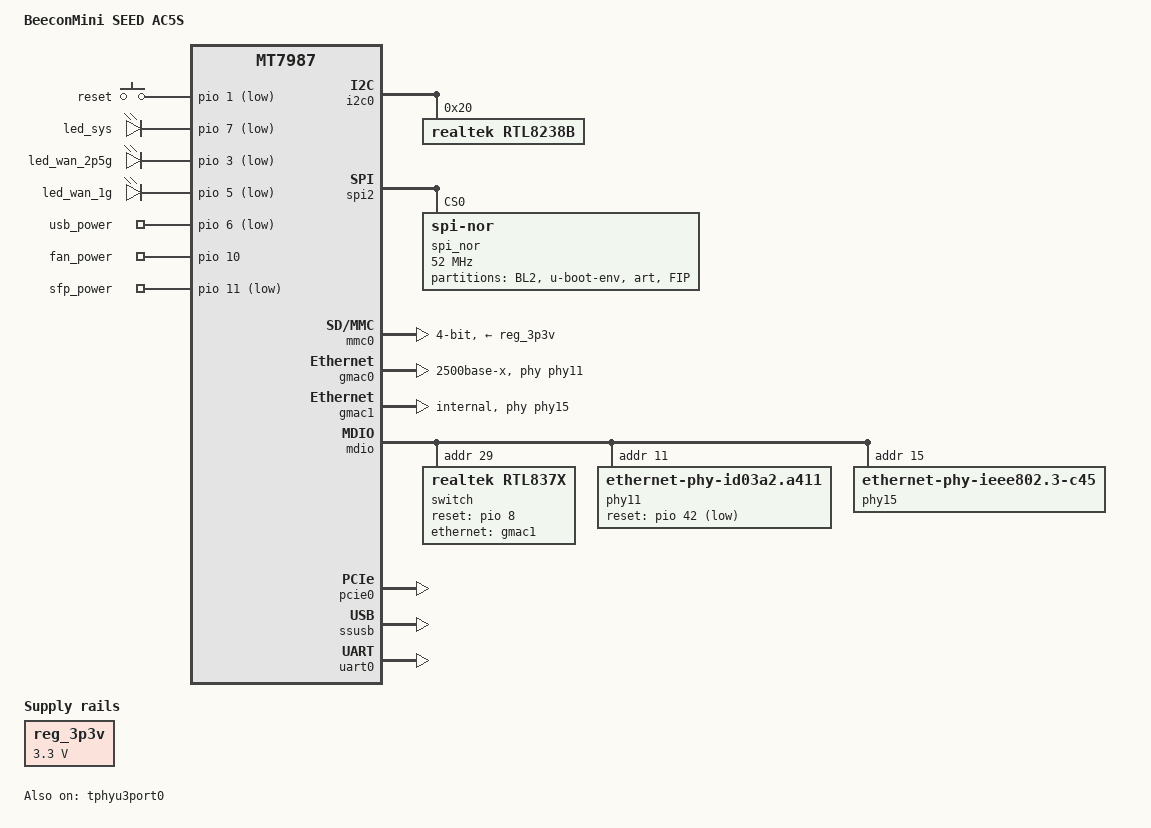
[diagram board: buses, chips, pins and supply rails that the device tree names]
// SPDX-License-Identifier: (GPL-2.0 OR MIT)
//
// BeeconMini SEED AC5S (eMMC/SD 变体) — kernel 6.18 / immortalwrt
// 基准: BeeconMini/immortalwrt 25.12.1 分支同名 DTS
// 改动: 交换芯片节点从 BeeconMini 闭源绑定 (realtek,rtl8373n + mediatek,mdio)
//       转换为社区开源驱动 rtl837x-gsw 的绑定 (realtek,rtl837x, mdio 子节点)

/dts-v1/;
#include "mt7987a.dtsi"
#include <dt-bindings/input/input.h>

/ {
	model = "BeeconMini SEED AC5S";
	compatible = "beeconmini,seed-ac5s", "mediatek,mt7987a", "mediatek,mt7987";

	aliases {
		label-mac-device = &gmac0;
		led-boot = &led_power;
		led-failsafe = &led_power;
		led-running = &led_power;
		led-upgrade = &led_power;
	};

	chosen {
		bootargs = "console=ttyS0,115200n1 \
			    earlycon=uart8250,mmio32,0x11000000 \
			    pci=pcie_bus_perf \
			    root=PARTLABEL=rootfs rootfstype=squashfs,f2fs \
			    rootwait fstools_partname_fallback_scan=1";
	};

	aliases {
		led-boot = &led_sys;
		led-failsafe = &led_sys;
		led-running = &led_sys;
		led-upgrade = &led_sys;
	};

	gpio-keys {
		compatible = "gpio-keys";

		reset {
			label = "reset";
			linux,code = <KEY_RESTART>;
			gpios = <&pio 1 GPIO_ACTIVE_LOW>;
			debounce-interval = <10>;
		};
	};

	gpio-leds {
		compatible = "gpio-leds";

		led_sys: led@0 {
			label = "led_sys";
			gpios = <&pio 7 GPIO_ACTIVE_LOW>;
		};

		led_wan_2p5g: led@1 {
			label = "led_wan_2p5g";
			gpios = <&pio 3 GPIO_ACTIVE_LOW>;
		};

		led_wan_1g: led@2 {
			label = "led_wan_1g";
			gpios = <&pio 5 GPIO_ACTIVE_LOW>;
		};
	};

	gpio-export {
		compatible = "gpio-export";
		#size-cells = <0>;

		usb {
			gpio-export,name = "usb_power";
			gpio-export,output = <0>;
			gpios = <&pio 6 GPIO_ACTIVE_LOW>;
		};

		fan {
			gpio-export,name = "fan_power";
			gpio-export,output = <0>;
			gpios = <&pio 10 GPIO_ACTIVE_HIGH>;
		};

		sfp {
			gpio-export,name = "sfp_power";
			gpio-export,output = <1>;
			gpios = <&pio 11 GPIO_ACTIVE_LOW>;
		};
	};

	reg_3p3v: regulator-3p3v {
		compatible = "regulator-fixed";
		regulator-name = "fixed-3.3V";
		regulator-min-microvolt = <3300000>;
		regulator-max-microvolt = <3300000>;
		regulator-boot-on;
		regulator-always-on;
	};
};

&i2c0 {
	status = "okay";
	rtl8238b: rtl8238b@20 {
		compatible = "realtek,rtl8238b";
		reg = <0x20>;
	};
};

&spi1 {
	status = "disabled";
};

&spi2 {
	status = "okay";

	spi_nor: spi_nor@0 {
		#address-cells = <1>;
		#size-cells = <1>;
		compatible = "jedec,spi-nor";
		reg = <0>;
		spi-max-frequency = <52000000>;
		spi-tx-bus-width = <4>;
		spi-rx-bus-width = <4>;

		partitions {
			compatible = "fixed-partitions";
			#address-cells = <1>;
			#size-cells = <1>;

			partition@00000 {
				label = "BL2";
				reg = <0x00000 0x0040000>;
				read-only;
			};

			partition@40000 {
				label = "u-boot-env";
				reg = <0x40000 0x0010000>;
			};

			art: partition@50000 {
				label = "art";
				reg = <0x50000 0x0010000>;

				nvmem-layout {
					compatible = "fixed-layout";
					#address-cells = <1>;
					#size-cells = <1>;

					macaddr_base: macaddr@0 {
						reg = <0x0 0x6>;
						compatible = "mac-base";
						#nvmem-cell-cells = <1>;
					};
				};
			};

			partition@60000 {
				label = "FIP";
				reg = <0x60000 0x0200000>;
				read-only;
			};
		};
	};
};

&mmc0 {
	pinctrl-names = "default", "state_uhs";
	pinctrl-0 = <&mmc_pins_default>;
	pinctrl-1 = <&mmc_pins_uhs>;
	bus-width = <4>;
	max-frequency = <48000000>;
	cap-sd-highspeed;
	no-mmc;
	no-sdio;
	vmmc-supply = <&reg_3p3v>;
	vqmmc-supply = <&reg_3p3v>;
	status = "okay";
	#address-cells = <1>;
	#size-cells = <0>;
};

&gmac0 {
	compatible = "mediatek,eth-mac";
	reg = <0>;
	mac-type = "gdm";
	phy-mode = "2500base-x";
	phy-handle = <&phy11>;
	status = "okay";
	nvmem-cells = <&macaddr_base 1>;
	nvmem-cell-names = "mac-address";
};

&gmac1 {
	phy-mode = "internal";
	phy-handle = <&phy15>;
	status = "okay";
	nvmem-cells = <&macaddr_base 0>;
	nvmem-cell-names = "mac-address";
};

&mdio {
	/*
	 * RTL8373N 交换芯片 — 社区开源驱动 rtl837x-gsw (kmod-switch-rtl837x)
	 *
	 * 原 BeeconMini 闭源驱动节点:
	 *   rtl8373n { compatible = "realtek,rtl8373n"; mediatek,mdio = <&mdio>;
	 *              mediatek,reset-pin = <&pio 8 GPIO_ACTIVE_HIGH>;
	 *              interrupts = <11 IRQ_TYPE_LEVEL_LOW>; };
	 *
	 * 以下值已于 2026-08-14 实机确认 (官方固件 25.12.3 @ 192.168.10.140):
	 *  - reg = 29 (0x1d): 闭源驱动 rtl8373_smi_read 反汇编硬编码 0x1d;
	 *        邮箱协议读回 chip ID 0x83737000 (= RTL8373N)。总线扫描仅 0x1d
	 *        响应邮箱窗口 (0x15-0x18), 标准 PHY 寄存器不响应。
	 *  - rtl837x,cpu-port = 7: 官方 dmesg "<rtl8373> port:7 link UP - 2.5Gbps";
	 *        上行 gmac1→phy15(内部 2.5G 铜 PHY)→交换芯片电口 7; 且 SDS0/1 均
	 *        配置为 10G 模式 (非上行)。CPU 口不是 serdes 口, 驱动会跳过 serdes 复位。
	 *  - rtl837x,sds0mode = "10g-qxg": 运行态 0x7B20=0x0b4d, SDS0 mode=0xD
	 *        (10GUSXG) + sub-mode 2 — 与开放驱动 "10g-qxg" 写入的字节完全一致
	 *        (SDS0 接 RTL8224N 10G PHY → SFP+ 笼)。
	 *  - SFP+ 默认速率 = 10G: sds0mode "10g-qxg" 固定 (与官方固件一致, 无协商);
	 *        10G 光模块需接对端设备才有 link (无对端无 link 属正常), 2.5G 光模块不协商。
	 *  - rtl837x,sds1mode = "10g-kr": 运行态 SDS1 mode=0x1A (10GR)。
	 *  - reset-gpios: pio8 GPIO_ACTIVE_HIGH — 官方 DTS mediatek,reset-pin=<&pio 8 0>;
	 *        运行态 debugfs gpio-520 "mediatek,reset-pin" out hi (高=运行)。
	 *  - 总线 0x13 有一个未用响应者 (r2=0x1a75, 非邮箱设备), 官方固件不访问;
	 *        与本次集成无关。
	 *  - 10G SFP+ 完整支持 (sfp 节点/8224N) 为后续项, 按 rtl837x-gsw-driver README。
	 */
	switch@1d {
		compatible = "realtek,rtl837x";
		reg = <29>;
		reset-gpios = <&pio 8 GPIO_ACTIVE_HIGH>;
		rtl837x,cpu-port = <7>;
		rtl837x,sds0mode = "10g-qxg";
		rtl837x,sds1mode = "10g-kr";
		ethernet = <&gmac1>;
		status = "okay";
		/*
		 * 前面板 LED 配置 — 提取自官方闭源驱动 rtl8373n.ko 的
		 * rtl8373N_8224N_init 内联 LED 初始化 (2026-08-20 反汇编确认, 实机验证通过):
		 *  - 端口对齐: LAN N = 交换端口 8-N (面板顺序与交换端口反转, 实机确认:
		 *    LAN 2=port6 ... LAN 8=port0), 各口点亮自己位置的灯 (绿/橙双色)
		 *  - 颜色: 绿 = 2.5G/10G (LED2 = 0x141 + 10G), 橙 = 1G/500M/100M (LED0 = 0x174)
		 *  - 注意: 官方同时写 0x6520=0x428 (上电LED位); 6.18 无上电完成握手会导致
		 *    某口绿灯常亮, 故此处不写 0x6520, 保持芯片默认 0x0021ddb0 (实机验证: 无恒亮)
		 */
		extra-init =
			<0x65f8 0x3 0x3>,
			<0x65fc 0xffffffff 0x33333333>,
			<0x6600 0xf 0x3>,
			<0x6548 0xffff 0x174>,
			<0x6548 0xffff0000 0x174>,
			<0x6528 0xf 0x0>,
			<0x6528 0xf0 0x0>,
			<0x6544 0xffff 0x141>,
			<0x6544 0xffff0000 0x141>,
			<0x6528 0xf00 0x1>,
			<0x6528 0xf000 0x1>,
			<0x654c 0x3 0x0>,
			<0x654c 0xc 0x0>,
			<0x654c 0x30 0x0>,
			<0x654c 0xc0 0x0>,
			<0x654c 0x300 0x0>,
			<0x654c 0xc00 0x0>,
			<0x654c 0x3000 0x0>,
			<0x654c 0xc000 0x0>,
			<0x654c 0x30000 0x0>,
			<0x65e0 0x3f 0x2>,
			<0x65e0 0xfc0 0x0>,
			<0x65e0 0x3f000 0x6>,
			<0x65e0 0xfc0000 0x4>,
			<0x65e0 0x3f000000 0xa>,
			<0x65e4 0x3f 0x8>,
			<0x65e4 0xfc0 0xe>,
			<0x65e4 0xfc0000 0xc>,
			<0x65e4 0x3f000000 0x12>,
			<0x65e8 0x3f 0x10>,
			<0x65e8 0x3f000 0x16>,
			<0x65ec 0x3f 0x14>,
			<0x65ec 0xfc0000 0x1a>,
			<0x65f0 0xfc0 0x18>,
			<0x65f0 0x3f000000 0x1e>,
			<0x65f4 0x3f 0x1c>,
			<0x65f4 0xfc0 0x22>,
			<0x65f4 0x3f000 0x20>,
			<0x65d8 0x1 0x0>,
			<0x65d8 0x2 0x1>,
			<0x65d8 0x4 0x1>,
			<0x65d8 0x8 0x0>,
			<0x65d8 0x10 0x1>,
			<0x65d8 0x20 0x1>,
			<0x65d8 0x40 0x1>,
			<0x65d8 0x100 0x1>,
			<0x65d8 0x200 0x1>,
			<0x65d8 0x400 0x1>,
			<0x65d8 0x1000 0x1>,
			<0x65d8 0x8000 0x0>,
			<0x65d8 0x40000 0x0>,
			<0x65d8 0x200000 0x1>,
			<0x65d8 0x1000000 0x0>,
			<0x65d8 0x2000000 0x1>,
			<0x65d8 0x4000000 0x1>,
			<0x65d8 0x8000000 0x1>,
			<0x65dc 0x3fffffff 0x3fffffff>;
	};

	phy11: phy@11 {
		compatible = "ethernet-phy-id03a2.a411";
		reg = <11>;
		phy-mode = "2500base-x";
		airoha,polarity = <1>;
		airoha,surge = <0>;
		airoha,phy-handle;
		reset-gpios = <&pio 42 GPIO_ACTIVE_LOW>;
		reset-assert-us = <10000>;
		reset-deassert-us = <10000>;
	};

	phy15: phy@15 {
		pinctrl-names = "i2p5gbe-led";
		pinctrl-0 = <&i2p5gbe_led0_pins>;
		compatible = "ethernet-phy-ieee802.3-c45";
		reg = <15>;
		phy-mode = "internal";
	};
};

&pcie0 {
	pinctrl-names = "default";
	pinctrl-0 = <&pcie0_pins>;
	status = "okay";
};

&pcie1 {
	status = "disabled";
};

&ssusb {
	status = "okay";
};

&tphyu3port0 {
	status = "okay";
};

&uart0 {
	pinctrl-names = "default";
	pinctrl-0 = <&uart0_pins>;
	status = "okay";
};
